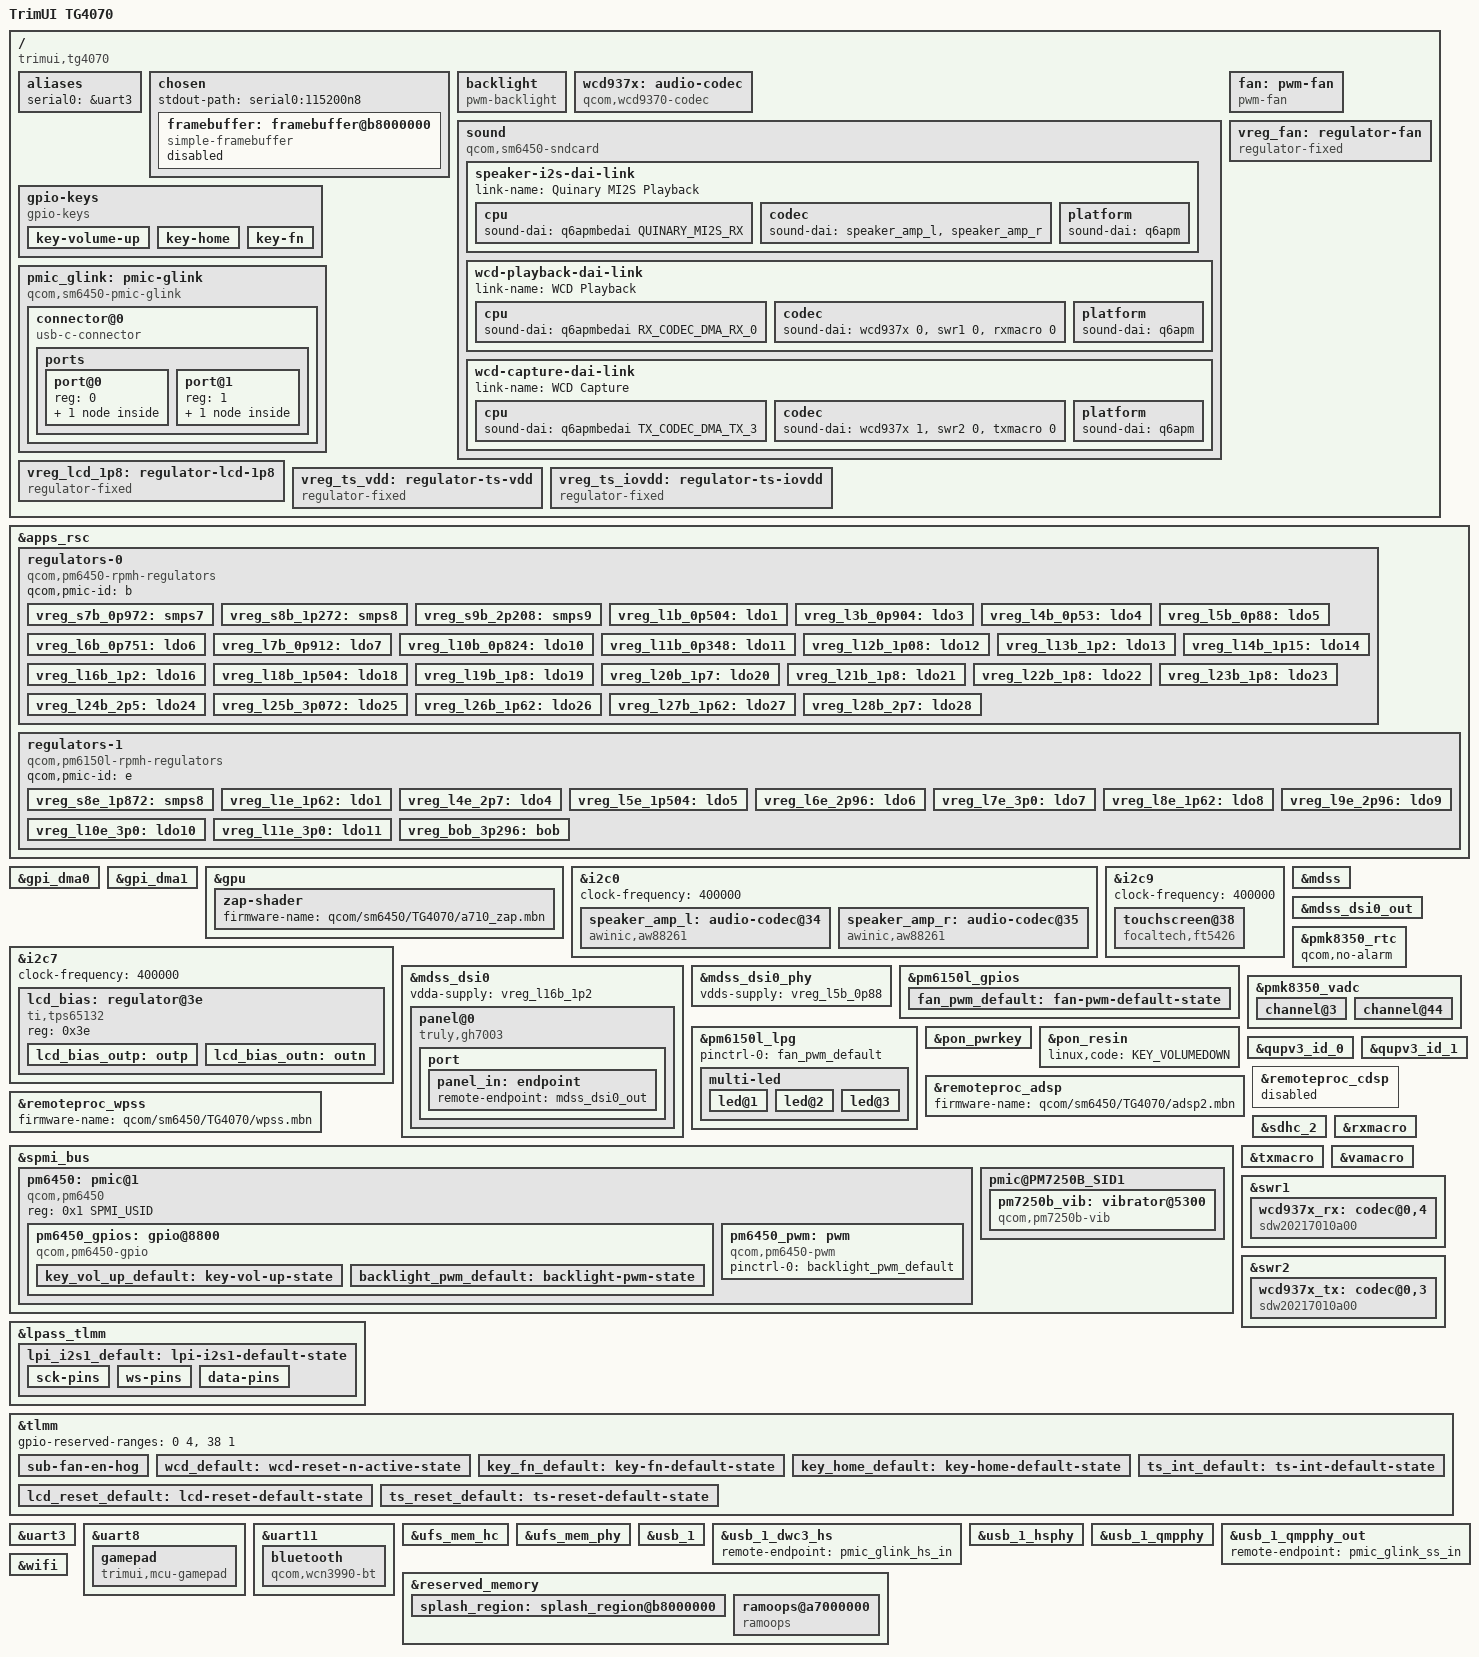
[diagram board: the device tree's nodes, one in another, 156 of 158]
// SPDX-License-Identifier: BSD-3-Clause
/*
 * TrimUI TG4070 (Snapdragon G2 Gen 1)
 */

/dts-v1/;

#include <dt-bindings/clock/qcom,dsi-phy-28nm.h>
#include <dt-bindings/gpio/gpio.h>
#include <dt-bindings/iio/qcom,spmi-adc7-pmk8350.h>
#include <dt-bindings/iio/qcom,spmi-vadc.h>
#include <dt-bindings/input/input.h>
#include <dt-bindings/leds/common.h>
#include <dt-bindings/pinctrl/qcom,pmic-gpio.h>
#include <dt-bindings/regulator/qcom,rpmh-regulator.h>
#include <dt-bindings/sound/qcom,q6dsp-lpass-ports.h>
#include <dt-bindings/spmi/spmi.h>
#define PM7250B_SID 8
#define PM7250B_SID1 9
#include "sm6450.dtsi"
#include "pm6150l.dtsi"
#include "pm7250b.dtsi"
#include "pmk8350.dtsi"

/ {
	model = "TrimUI TG4070";
	compatible = "trimui,tg4070", "qcom,sm6450";
	qcom,msm-id = <0x27a 0x10000>, <0x279 0x10000>,
		      <0x219 0x10000>, <0x265 0x10000>;
	qcom,board-id = <0x1000b 0>;

	aliases {
		serial0 = &uart3;
	};

	chosen {
		#address-cells = <2>;
		#size-cells = <2>;
		ranges;
		stdout-path = "serial0:115200n8";

		framebuffer: framebuffer@b8000000 {
			compatible = "simple-framebuffer";
			reg = <0x0 0xb8000000 0x0 0x300000>;
			width = <1024>;
			height = <768>;
			stride = <4096>;
			format = "a8r8g8b8";
			status = "disabled";
		};
	};

	backlight: backlight {
		compatible = "pwm-backlight";
		pwms = <&pm6450_pwm 0 80000>;
		brightness-levels = <0 3 6 10 15 23 32 43 57 74 94
				     117 144 174 208 247 290 337 390 448 511>;
		num-interpolated-steps = <200>;
		default-brightness-level = <2000>;
	};

	wcd937x: audio-codec {
		compatible = "qcom,wcd9370-codec";
		pinctrl-0 = <&wcd_default>;
		pinctrl-names = "default";
		reset-gpios = <&tlmm 102 GPIO_ACTIVE_LOW>;
		vdd-buck-supply = <&vreg_l20b_1p7>;
		vdd-rxtx-supply = <&vreg_l21b_1p8>;
		vdd-px-supply = <&vreg_l21b_1p8>;
		vdd-mic-bias-supply = <&vreg_bob_3p296>;
		qcom,micbias1-microvolt = <1800000>;
		qcom,micbias2-microvolt = <1800000>;
		qcom,micbias3-microvolt = <1800000>;
		qcom,hphl-jack-type-normally-closed;
		qcom,ground-jack-type-normally-closed;
		qcom,mbhc-buttons-vthreshold-microvolt = <75000 150000 237000 500000 500000 500000 500000 500000>;
		qcom,mbhc-headset-vthreshold-microvolt = <1700000>;
		qcom,mbhc-headphone-vthreshold-microvolt = <50000>;
		qcom,rx-device = <&wcd937x_rx>;
		qcom,tx-device = <&wcd937x_tx>;
		#sound-dai-cells = <1>;
	};

	sound {
		compatible = "qcom,sm6450-sndcard", "qcom,sm8450-sndcard";
		model = "TrimUI-TG4070";
		audio-routing = "IN1_HPHL", "HPHL_OUT",
				"IN2_HPHR", "HPHR_OUT",
				"AMIC2", "MIC BIAS2",
				"TX SWR_INPUT1", "ADC2_OUTPUT";
		pinctrl-0 = <&lpi_i2s1_default>;
		pinctrl-names = "default";

		clocks = <&q6prmcc LPASS_CLK_ID_QUI_MI2S_IBIT LPASS_CLK_ATTRIBUTE_COUPLE_NO>;
		clock-names = "i2s_clk";
		assigned-clocks = <&q6prmcc LPASS_CLK_ID_QUI_MI2S_IBIT LPASS_CLK_ATTRIBUTE_COUPLE_NO>;
		assigned-clock-rates = <1536000>;

		speaker-i2s-dai-link {
			link-name = "Quinary MI2S Playback";

			cpu {
				sound-dai = <&q6apmbedai QUINARY_MI2S_RX>;
			};

			codec {
				sound-dai = <&speaker_amp_l>, <&speaker_amp_r>;
			};

			platform {
				sound-dai = <&q6apm>;
			};
		};

		wcd-playback-dai-link {
			link-name = "WCD Playback";

			cpu {
				sound-dai = <&q6apmbedai RX_CODEC_DMA_RX_0>;
			};

			codec {
				sound-dai = <&wcd937x 0>, <&swr1 0>, <&rxmacro 0>;
			};

			platform {
				sound-dai = <&q6apm>;
			};
		};

		wcd-capture-dai-link {
			link-name = "WCD Capture";

			cpu {
				sound-dai = <&q6apmbedai TX_CODEC_DMA_TX_3>;
			};

			codec {
				sound-dai = <&wcd937x 1>, <&swr2 0>, <&txmacro 0>;
			};

			platform {
				sound-dai = <&q6apm>;
			};
		};
	};

	fan: pwm-fan {
		compatible = "pwm-fan";
		pwms = <&pm6150l_lpg 4 40000>;
		fan-supply = <&vreg_fan>;
		#cooling-cells = <2>;
		cooling-levels = <0 1 20 30 40 50 60 70 80 90 100 110 120 130
				  140 150 160 170 190 208 218 220 222 224 226
				  227 228 229 230 232 235 240>;
	};

	gpio-keys {
		compatible = "gpio-keys";
		label = "gpio-keys";
		pinctrl-0 = <&key_vol_up_default>, <&key_home_default>, <&key_fn_default>;
		pinctrl-names = "default";

		key-volume-up {
			label = "Volume Up";
			gpios = <&pm6450_gpios 1 GPIO_ACTIVE_LOW>;
			linux,code = <KEY_VOLUMEUP>;
			debounce-interval = <15>;
			wakeup-source;
		};

		key-home {
			label = "Home";
			gpios = <&tlmm 71 GPIO_ACTIVE_LOW>;
			linux,code = <KEY_HOME>;
			debounce-interval = <15>;
			wakeup-source;
		};

		key-fn {
			label = "Fn";
			gpios = <&tlmm 72 GPIO_ACTIVE_LOW>;
			linux,code = <KEY_FN>;
			debounce-interval = <15>;
		};
	};

	pmic_glink: pmic-glink {
		compatible = "qcom,sm6450-pmic-glink", "qcom,pmic-glink";
		#address-cells = <1>;
		#size-cells = <0>;

		connector@0 {
			compatible = "usb-c-connector";
			reg = <0>;
			power-role = "dual";
			data-role = "dual";

			ports {
				#address-cells = <1>;
				#size-cells = <0>;

				port@0 {
					reg = <0>;

					pmic_glink_hs_in: endpoint {
						remote-endpoint = <&usb_1_dwc3_hs>;
					};
				};

				port@1 {
					reg = <1>;

					pmic_glink_ss_in: endpoint {
						remote-endpoint = <&usb_1_qmpphy_out>;
					};
				};
			};
		};
	};

	vreg_lcd_1p8: regulator-lcd-1p8 {
		compatible = "regulator-fixed";
		regulator-name = "vreg_lcd_1p8";
		regulator-min-microvolt = <1800000>;
		regulator-max-microvolt = <1800000>;
		regulator-boot-on;
		regulator-always-on;
		gpio = <&tlmm 30 GPIO_ACTIVE_HIGH>;
		enable-active-high;
	};

	vreg_ts_vdd: regulator-ts-vdd {
		compatible = "regulator-fixed";
		regulator-name = "vreg_ts_vdd";
		regulator-min-microvolt = <3300000>;
		regulator-max-microvolt = <3300000>;
		gpio = <&tlmm 6 GPIO_ACTIVE_HIGH>;
		enable-active-high;
	};

	vreg_ts_iovdd: regulator-ts-iovdd {
		compatible = "regulator-fixed";
		regulator-name = "vreg_ts_iovdd";
		regulator-min-microvolt = <1800000>;
		regulator-max-microvolt = <1800000>;
		gpio = <&tlmm 7 GPIO_ACTIVE_HIGH>;
		enable-active-high;
	};

	vreg_fan: regulator-fan {
		compatible = "regulator-fixed";
		regulator-name = "vreg_fan";
		gpio = <&tlmm 75 GPIO_ACTIVE_HIGH>;
		enable-active-high;
	};
};

&apps_rsc {
	regulators-0 {
		compatible = "qcom,pm6450-rpmh-regulators";
		qcom,pmic-id = "b";


		vreg_s7b_0p972: smps7 {
			regulator-name = "vreg_s7b_0p972";
			regulator-min-microvolt = <880000>;
			regulator-max-microvolt = <1174000>;
			regulator-initial-mode = <RPMH_REGULATOR_MODE_HPM>;
		};

		vreg_s8b_1p272: smps8 {
			regulator-name = "vreg_s8b_1p272";
			regulator-min-microvolt = <1224000>;
			regulator-max-microvolt = <1654000>;
			regulator-initial-mode = <RPMH_REGULATOR_MODE_HPM>;
		};

		vreg_s9b_2p208: smps9 {
			regulator-name = "vreg_s9b_2p208";
			regulator-min-microvolt = <850000>;
			regulator-max-microvolt = <2208000>;
			regulator-initial-mode = <RPMH_REGULATOR_MODE_HPM>;
		};

		vreg_l1b_0p504: ldo1 {
			regulator-name = "vreg_l1b_0p504";
			regulator-min-microvolt = <300000>;
			regulator-max-microvolt = <650000>;
			regulator-initial-mode = <RPMH_REGULATOR_MODE_HPM>;
		};

		vreg_l3b_0p904: ldo3 {
			regulator-name = "vreg_l3b_0p904";
			regulator-min-microvolt = <870000>;
			regulator-max-microvolt = <970000>;
			regulator-initial-mode = <RPMH_REGULATOR_MODE_HPM>;
		};

		vreg_l4b_0p53: ldo4 {
			regulator-name = "vreg_l4b_0p53";
			regulator-min-microvolt = <530000>;
			regulator-max-microvolt = <864000>;
			regulator-initial-mode = <RPMH_REGULATOR_MODE_HPM>;
		};

		vreg_l5b_0p88: ldo5 {
			regulator-name = "vreg_l5b_0p88";
			regulator-min-microvolt = <830000>;
			regulator-max-microvolt = <920000>;
			regulator-initial-mode = <RPMH_REGULATOR_MODE_HPM>;
		};

		vreg_l6b_0p751: ldo6 {
			regulator-name = "vreg_l6b_0p751";
			regulator-min-microvolt = <751000>;
			regulator-max-microvolt = <824000>;
			regulator-initial-mode = <RPMH_REGULATOR_MODE_HPM>;
		};

		vreg_l7b_0p912: ldo7 {
			regulator-name = "vreg_l7b_0p912";
			regulator-min-microvolt = <830000>;
			regulator-max-microvolt = <920000>;
			regulator-initial-mode = <RPMH_REGULATOR_MODE_HPM>;
		};


		vreg_l10b_0p824: ldo10 {
			regulator-name = "vreg_l10b_0p824";
			regulator-min-microvolt = <824000>;
			regulator-max-microvolt = <950000>;
			regulator-initial-mode = <RPMH_REGULATOR_MODE_HPM>;
		};

		vreg_l11b_0p348: ldo11 {
			regulator-name = "vreg_l11b_0p348";
			regulator-min-microvolt = <348000>;
			regulator-max-microvolt = <888000>;
			regulator-initial-mode = <RPMH_REGULATOR_MODE_HPM>;
		};

		vreg_l12b_1p08: ldo12 {
			regulator-name = "vreg_l12b_1p08";
			regulator-min-microvolt = <1080000>;
			regulator-max-microvolt = <1240000>;
			regulator-initial-mode = <RPMH_REGULATOR_MODE_HPM>;
		};

		vreg_l13b_1p2: ldo13 {
			regulator-name = "vreg_l13b_1p2";
			regulator-min-microvolt = <1080000>;
			regulator-max-microvolt = <1304000>;
			regulator-initial-mode = <RPMH_REGULATOR_MODE_HPM>;
		};

		vreg_l14b_1p15: ldo14 {
			regulator-name = "vreg_l14b_1p15";
			regulator-min-microvolt = <1150000>;
			regulator-max-microvolt = <1304000>;
			regulator-initial-mode = <RPMH_REGULATOR_MODE_HPM>;
		};

		vreg_l16b_1p2: ldo16 {
			regulator-name = "vreg_l16b_1p2";
			regulator-min-microvolt = <1140000>;
			regulator-max-microvolt = <1260000>;
			regulator-initial-mode = <RPMH_REGULATOR_MODE_HPM>;
		};

		vreg_l18b_1p504: ldo18 {
			regulator-name = "vreg_l18b_1p504";
			regulator-min-microvolt = <1504000>;
			regulator-max-microvolt = <2000000>;
			regulator-initial-mode = <RPMH_REGULATOR_MODE_HPM>;
		};

		vreg_l19b_1p8: ldo19 {
			regulator-name = "vreg_l19b_1p8";
			regulator-min-microvolt = <1620000>;
			regulator-max-microvolt = <1980000>;
			regulator-initial-mode = <RPMH_REGULATOR_MODE_HPM>;
		};

		vreg_l20b_1p7: ldo20 {
			regulator-name = "vreg_l20b_1p7";
			regulator-min-microvolt = <1700000>;
			regulator-max-microvolt = <1900000>;
			regulator-initial-mode = <RPMH_REGULATOR_MODE_HPM>;
		};

		vreg_l21b_1p8: ldo21 {
			regulator-name = "vreg_l21b_1p8";
			regulator-min-microvolt = <1800000>;
			regulator-max-microvolt = <1950000>;
			regulator-initial-mode = <RPMH_REGULATOR_MODE_HPM>;
		};

		vreg_l22b_1p8: ldo22 {
			regulator-name = "vreg_l22b_1p8";
			regulator-min-microvolt = <1800000>;
			regulator-max-microvolt = <2000000>;
			regulator-initial-mode = <RPMH_REGULATOR_MODE_HPM>;
		};

		vreg_l23b_1p8: ldo23 {
			regulator-name = "vreg_l23b_1p8";
			regulator-min-microvolt = <1650000>;
			regulator-max-microvolt = <1950000>;
			regulator-initial-mode = <RPMH_REGULATOR_MODE_HPM>;
		};

		/* UFS VCC; the vendor DT leaves the range open, TODO confirm */
		/* TODO: Fix properly UFS VCC: the SKhynix part never answers */
		vreg_l24b_2p5: ldo24 {
			regulator-name = "vreg_l24b_2p5";
			regulator-min-microvolt = <2504000>;
			regulator-max-microvolt = <2950000>;
			regulator-initial-mode = <RPMH_REGULATOR_MODE_HPM>;
			regulator-always-on;
		};

		vreg_l25b_3p072: ldo25 {
			regulator-name = "vreg_l25b_3p072";
			regulator-min-microvolt = <2700000>;
			regulator-max-microvolt = <3544000>;
			regulator-initial-mode = <RPMH_REGULATOR_MODE_HPM>;
		};

		vreg_l26b_1p62: ldo26 {
			regulator-name = "vreg_l26b_1p62";
			regulator-min-microvolt = <1620000>;
			regulator-max-microvolt = <3300000>;
			regulator-initial-mode = <RPMH_REGULATOR_MODE_HPM>;
		};

		vreg_l27b_1p62: ldo27 {
			regulator-name = "vreg_l27b_1p62";
			regulator-min-microvolt = <1620000>;
			regulator-max-microvolt = <3300000>;
			regulator-initial-mode = <RPMH_REGULATOR_MODE_HPM>;
		};

		vreg_l28b_2p7: ldo28 {
			regulator-name = "vreg_l28b_2p7";
			regulator-min-microvolt = <2700000>;
			regulator-max-microvolt = <3544000>;
			regulator-initial-mode = <RPMH_REGULATOR_MODE_HPM>;
		};
	};

	regulators-1 {
		compatible = "qcom,pm6150l-rpmh-regulators";
		qcom,pmic-id = "e";

		vreg_s8e_1p872: smps8 {
			regulator-name = "vreg_s8e_1p872";
			regulator-min-microvolt = <1816000>;
			regulator-max-microvolt = <2040000>;
			regulator-initial-mode = <RPMH_REGULATOR_MODE_HPM>;
		};

		vreg_l1e_1p62: ldo1 {
			regulator-name = "vreg_l1e_1p62";
			regulator-min-microvolt = <1620000>;
			regulator-max-microvolt = <1980000>;
			regulator-initial-mode = <RPMH_REGULATOR_MODE_HPM>;
		};

		vreg_l4e_2p7: ldo4 {
			regulator-name = "vreg_l4e_2p7";
			regulator-min-microvolt = <2700000>;
			regulator-max-microvolt = <3300000>;
			regulator-initial-mode = <RPMH_REGULATOR_MODE_HPM>;
		};

		vreg_l5e_1p504: ldo5 {
			regulator-name = "vreg_l5e_1p504";
			regulator-min-microvolt = <1504000>;
			regulator-max-microvolt = <3544000>;
			regulator-initial-mode = <RPMH_REGULATOR_MODE_HPM>;
		};

		vreg_l6e_2p96: ldo6 {
			regulator-name = "vreg_l6e_2p96";
			regulator-min-microvolt = <1800000>;
			regulator-max-microvolt = <2960000>;
			regulator-initial-mode = <RPMH_REGULATOR_MODE_HPM>;
		};

		vreg_l7e_3p0: ldo7 {
			regulator-name = "vreg_l7e_3p0";
			regulator-min-microvolt = <3000000>;
			regulator-max-microvolt = <3544000>;
			regulator-initial-mode = <RPMH_REGULATOR_MODE_HPM>;
		};

		vreg_l8e_1p62: ldo8 {
			regulator-name = "vreg_l8e_1p62";
			regulator-min-microvolt = <1620000>;
			regulator-max-microvolt = <2000000>;
			regulator-initial-mode = <RPMH_REGULATOR_MODE_HPM>;
		};

		vreg_l9e_2p96: ldo9 {
			regulator-name = "vreg_l9e_2p96";
			regulator-min-microvolt = <2952000>;
			regulator-max-microvolt = <2960000>;
			regulator-initial-mode = <RPMH_REGULATOR_MODE_HPM>;
		};

		vreg_l10e_3p0: ldo10 {
			regulator-name = "vreg_l10e_3p0";
			regulator-min-microvolt = <3000000>;
			regulator-max-microvolt = <3400000>;
			regulator-initial-mode = <RPMH_REGULATOR_MODE_HPM>;
		};

		vreg_l11e_3p0: ldo11 {
			regulator-name = "vreg_l11e_3p0";
			regulator-min-microvolt = <3000000>;
			regulator-max-microvolt = <3400000>;
			regulator-initial-mode = <RPMH_REGULATOR_MODE_HPM>;
		};

		vreg_bob_3p296: bob {
			regulator-name = "vreg_bob_3p296";
			regulator-min-microvolt = <3008000>;
			regulator-max-microvolt = <3960000>;
			regulator-initial-mode = <RPMH_REGULATOR_MODE_AUTO>;
		};
	};

};

&gpi_dma0 {
	status = "okay";
};

&gpi_dma1 {
	status = "okay";
};

&gpu {
	status = "okay";

	zap-shader {
		firmware-name = "qcom/sm6450/TG4070/a710_zap.mbn";
	};
};

&i2c0 {
	clock-frequency = <400000>;
	status = "okay";

	speaker_amp_l: audio-codec@34 {
		compatible = "awinic,aw88261";
		reg = <0x34>;
		#sound-dai-cells = <0>;
		firmware-name = "qcom/sm6450/TG4070/aw88261_acf.bin";
		sound-name-prefix = "Left";
		awinic,audio-channel = <0>;
	};

	speaker_amp_r: audio-codec@35 {
		compatible = "awinic,aw88261";
		reg = <0x35>;
		#sound-dai-cells = <0>;
		firmware-name = "qcom/sm6450/TG4070/aw88261_acf.bin";
		sound-name-prefix = "Right";
		awinic,audio-channel = <1>;
	};
};

&i2c7 {
	clock-frequency = <400000>;
	status = "okay";

	lcd_bias: regulator@3e {
		compatible = "ti,tps65132";
		reg = <0x3e>;

		lcd_bias_outp: outp {
			regulator-name = "lcd_vsp";
			regulator-min-microvolt = <5800000>;
			regulator-max-microvolt = <5800000>;
			regulator-boot-on;
			regulator-always-on;
			enable-gpios = <&tlmm 36 GPIO_ACTIVE_HIGH>;
		};

		lcd_bias_outn: outn {
			regulator-name = "lcd_vsn";
			regulator-min-microvolt = <5800000>;
			regulator-max-microvolt = <5800000>;
			regulator-boot-on;
			regulator-always-on;
			enable-gpios = <&tlmm 37 GPIO_ACTIVE_HIGH>;
		};
	};
};

&i2c9 {
	clock-frequency = <400000>;
	status = "okay";

	touchscreen@38 {
		compatible = "focaltech,ft5426";
		reg = <0x38>;

		interrupt-parent = <&tlmm>;
		interrupts = <18 IRQ_TYPE_EDGE_FALLING>;
		reset-gpios = <&tlmm 78 GPIO_ACTIVE_LOW>;
		vcc-supply = <&vreg_ts_vdd>;
		iovcc-supply = <&vreg_ts_iovdd>;

		pinctrl-0 = <&ts_int_default>, <&ts_reset_default>;
		pinctrl-names = "default";

		touchscreen-size-x = <1024>;
		touchscreen-size-y = <768>;
	};
};

&mdss {
	status = "okay";
};

&mdss_dsi0 {
	vdda-supply = <&vreg_l16b_1p2>;
	status = "okay";

	panel@0 {
		compatible = "truly,gh7003";
		reg = <0>;

		reset-gpios = <&tlmm 98 GPIO_ACTIVE_LOW>;
		vddio-supply = <&vreg_lcd_1p8>;
		avdd-supply = <&lcd_bias_outp>;
		avee-supply = <&lcd_bias_outn>;
		backlight = <&backlight>;

		pinctrl-0 = <&lcd_reset_default>;
		pinctrl-names = "default";

		port {
			panel_in: endpoint {
				remote-endpoint = <&mdss_dsi0_out>;
			};
		};
	};
};

&mdss_dsi0_out {
	data-lanes = <0 1 2 3>;
	remote-endpoint = <&panel_in>;
};

&mdss_dsi0_phy {
	vdds-supply = <&vreg_l5b_0p88>;
	status = "okay";
};

&pm6150l_gpios {
	fan_pwm_default: fan-pwm-default-state {
		pins = "gpio10";
		function = "func1";
		input-disable;
		output-low;
		power-source = <1>;
		qcom,drive-strength = <PMIC_GPIO_STRENGTH_LOW>;
		bias-disable;
	};



};

&pm6150l_lpg {
	pinctrl-0 = <&fan_pwm_default>;
	pinctrl-names = "default";
	status = "okay";

	multi-led {
		color = <LED_COLOR_ID_RGB>;
		function = LED_FUNCTION_STATUS;
		#address-cells = <1>;
		#size-cells = <0>;

		led@1 {
			reg = <1>;
			color = <LED_COLOR_ID_RED>;
		};

		led@2 {
			reg = <2>;
			color = <LED_COLOR_ID_GREEN>;
		};

		led@3 {
			reg = <3>;
			color = <LED_COLOR_ID_BLUE>;
		};
	};
};

&pmk8350_rtc {
	qcom,no-alarm;
	status = "okay";
};

&pmk8350_vadc {
	channel@3 {
		reg = <PMK8350_ADC7_DIE_TEMP>;
		label = "pmk8350_die_temp";
		qcom,pre-scaling = <1 1>;
	};

	channel@44 {
		reg = <PMK8350_ADC7_AMUX_THM1_100K_PU>;
		label = "pmk8350_xo_therm";
		qcom,hw-settle-time = <200>;
		qcom,pre-scaling = <1 1>;
		qcom,ratiometric;
	};
};

&pon_pwrkey {
	status = "okay";
};

&pon_resin {
	linux,code = <KEY_VOLUMEDOWN>;
	status = "okay";
};

&qupv3_id_0 {
	status = "okay";
};

&qupv3_id_1 {
	status = "okay";
};

&remoteproc_adsp {
	firmware-name = "qcom/sm6450/TG4070/adsp2.mbn";
	status = "okay";
};

&remoteproc_cdsp {
	status = "disabled";
};

&remoteproc_wpss {
	firmware-name = "qcom/sm6450/TG4070/wpss.mbn";
	status = "okay";
};

&sdhc_2 {
	vmmc-supply = <&vreg_l9e_2p96>;
	vqmmc-supply = <&vreg_l6e_2p96>;

	cd-gpios = <&tlmm 107 GPIO_ACTIVE_LOW>;
	pinctrl-0 = <&sdc2_default>;
	pinctrl-names = "default";
	status = "okay";
};

&spmi_bus {
	pm6450: pmic@1 {
		compatible = "qcom,pm6450", "qcom,spmi-pmic";
		reg = <0x1 SPMI_USID>;
		#address-cells = <1>;
		#size-cells = <0>;

		pm6450_gpios: gpio@8800 {
			compatible = "qcom,pm6450-gpio", "qcom,spmi-gpio";
			reg = <0x8800>;
			gpio-controller;
			gpio-ranges = <&pm6450_gpios 0 0 9>;
			#gpio-cells = <2>;
			interrupt-controller;
			#interrupt-cells = <2>;

			key_vol_up_default: key-vol-up-state {
				pins = "gpio1";
				function = "normal";
				input-enable;
				bias-pull-up;
				power-source = <0>;
			};

			backlight_pwm_default: backlight-pwm-state {
				pins = "gpio7";
				function = "func1";
				input-disable;
				output-enable;
				power-source = <1>;
				qcom,drive-strength = <PMIC_GPIO_STRENGTH_LOW>;
				bias-disable;
			};
		};

		pm6450_pwm: pwm {
			compatible = "qcom,pm6450-pwm";
			#pwm-cells = <2>;
			pinctrl-0 = <&backlight_pwm_default>;
			pinctrl-names = "default";
		};
	};

	pmic@PM7250B_SID1 {
		pm7250b_vib: vibrator@5300 {
			compatible = "qcom,pm7250b-vib", "qcom,pmi632-vib";
			reg = <0x5300>;
			qcom,vib-max-microvolt = <2750000>;
		};
	};

};

&rxmacro {
	status = "okay";
};

&txmacro {
	status = "okay";
};

&vamacro {
	status = "okay";
};

&swr1 {
	status = "okay";

	wcd937x_rx: codec@0,4 {
		compatible = "sdw20217010a00";
		reg = <0 4>;
		qcom,rx-port-mapping = <1 2 3 4 5>;
	};
};

&swr2 {
	status = "okay";

	wcd937x_tx: codec@0,3 {
		compatible = "sdw20217010a00";
		reg = <0 3>;
		qcom,tx-port-mapping = <1 1 2 3>;
	};
};

&lpass_tlmm {
	lpi_i2s1_default: lpi-i2s1-default-state {
		sck-pins {
			pins = "gpio6";
			function = "i2s1_clk";
			drive-strength = <8>;
			bias-disable;
		};

		ws-pins {
			pins = "gpio7";
			function = "i2s1_ws";
			drive-strength = <8>;
			bias-disable;
		};

		data-pins {
			pins = "gpio8", "gpio9";
			function = "i2s1_data";
			drive-strength = <8>;
			bias-disable;
		};
	};
};

&tlmm {
	gpio-reserved-ranges = <0 4>, <38 1>;

	sub-fan-en-hog {
		gpio-hog;
		gpios = <69 GPIO_ACTIVE_HIGH>;
		output-high;
		line-name = "sub-fan-en";
	};

	wcd_default: wcd-reset-n-active-state {
		pins = "gpio102";
		function = "gpio";
		drive-strength = <16>;
		output-high;
	};

	key_fn_default: key-fn-default-state {
		pins = "gpio72";
		function = "gpio";
		drive-strength = <8>;
		bias-pull-up;
	};

	key_home_default: key-home-default-state {
		pins = "gpio71";
		function = "gpio";
		drive-strength = <2>;
		bias-pull-up;
	};

	lcd_reset_default: lcd-reset-default-state {
		pins = "gpio98";
		function = "gpio";
		drive-strength = <8>;
		bias-pull-up;
	};

	ts_int_default: ts-int-default-state {
		pins = "gpio18";
		function = "gpio";
		drive-strength = <8>;
		bias-pull-up;
	};

	ts_reset_default: ts-reset-default-state {
		pins = "gpio78";
		function = "gpio";
		drive-strength = <8>;
		bias-pull-up;
	};
};

&uart3 {
	status = "okay";
};

&uart8 {
	status = "okay";

	gamepad {
		compatible = "trimui,mcu-gamepad";
		power-gpios = <&tlmm 74 GPIO_ACTIVE_HIGH>;
		enable-gpios = <&tlmm 73 GPIO_ACTIVE_HIGH>;
		led-power-gpios = <&tlmm 70 GPIO_ACTIVE_HIGH>;
	};
};

&uart11 {
	status = "okay";

	bluetooth {
		compatible = "qcom,wcn3990-bt";
		vddio-supply = <&vreg_l22b_1p8>;
		vddxo-supply = <&vreg_l1e_1p62>;
		vddrf-supply = <&vreg_l14b_1p15>;
		vddch0-supply = <&vreg_l10e_3p0>;
		max-speed = <3200000>;
	};
};

&ufs_mem_hc {
	reset-gpios = <&tlmm 141 GPIO_ACTIVE_LOW>;
	vcc-supply = <&vreg_l24b_2p5>;
	vcc-max-microamp = <1200000>;
	vccq-supply = <&vreg_l13b_1p2>;
	vccq-max-microamp = <1200000>;
	status = "okay";
};

&ufs_mem_phy {
	vdda-phy-supply = <&vreg_l5b_0p88>;
	vdda-pll-supply = <&vreg_l16b_1p2>;
	status = "okay";
};

&usb_1 {
	dr_mode = "otg";
	usb-role-switch;
	role-switch-default-mode = "peripheral";
	status = "okay";
};

&usb_1_dwc3_hs {
	remote-endpoint = <&pmic_glink_hs_in>;
};

&usb_1_hsphy {
	vdda-pll-supply = <&vreg_l5b_0p88>;
	vdda18-supply = <&vreg_l23b_1p8>;
	vdda33-supply = <&vreg_l25b_3p072>;
	qcom,hs-disconnect-bp = <630>;
	qcom,squelch-detector-bp = <(-530)>;
	qcom,hs-amplitude-bp = <1780>;
	qcom,pre-emphasis-duration-bp = <20000>;
	qcom,pre-emphasis-amplitude-bp = <30000>;
	qcom,hs-rise-fall-time-bp = <0>;
	qcom,hs-crossover-voltage-microvolt = <0>;
	qcom,hs-output-impedance-micro-ohms = <2600000>;
	qcom,ls-fs-output-impedance-bp = <0>;
	status = "okay";
};

&usb_1_qmpphy {
	vdda-phy-supply = <&vreg_l7b_0p912>;
	vdda-pll-supply = <&vreg_l16b_1p2>;
	orientation-switch;
	status = "okay";
};

&usb_1_qmpphy_out {
	remote-endpoint = <&pmic_glink_ss_in>;
};

&wifi {
	vdd-0.8-cx-mx-supply = <&vreg_l11b_0p348>;
	vdd-1.8-xo-supply = <&vreg_l1e_1p62>;
	vdd-1.3-rfa-supply = <&vreg_l14b_1p15>;
	vdd-3.3-ch0-supply = <&vreg_l10e_3p0>;
	vdd-3.3-ch1-supply = <&vreg_l11e_3p0>;
	status = "okay";
};

/*TODO: REMOVE*/
&reserved_memory {
	splash_region: splash_region@b8000000 {
		reg = <0x0 0xb8000000 0x0 0x2b00000>;
		no-map;
	};

	ramoops@a7000000 {
		compatible = "ramoops";
		reg = <0x0 0xa7000000 0x0 0x100000>;
		record-size = <0x8000>;
		console-size = <0x80000>;
		pmsg-size = <0x8000>;
		ecc-size = <0>;
	};
};
